# V32F20x_CM33 register map
File version: 1.0.3
CPU: CM33 r0p4, little endian, MPU, FPU, DSP, 3 interrupt priority bits, 8 SAU regions
Registers are 32-bit, read-write, reset 0x0 unless marked. A register's access mark holds for its fields unless they carry their own. Offsets are from the block's base; [hi:lo] are bit positions.

## FLASHA — FLASHA Peripheral Interface
Base 0x40208000
Same registers: FLASHB 0x4020C000, FLASH0 0x41208000, SEC_FLASHA 0x50208000, SEC_FLASHB 0x5020C000
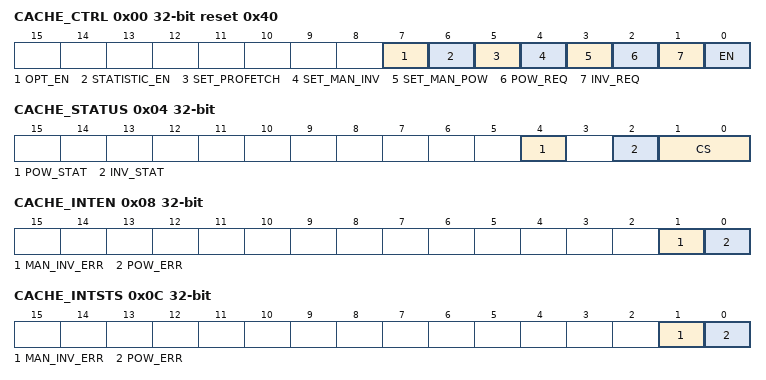
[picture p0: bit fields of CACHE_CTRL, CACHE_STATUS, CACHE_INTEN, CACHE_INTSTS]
0x00 CACHE_CTRL reset 0x40 — Flash cache Control register.
  [7] OPT_EN — Cache Performance Optimization enable control
  [6] STATISTIC_EN — Statistics logic enable control
  [5] SET_PROFETCH — Cache Pre-fetch enable control
  [4] SET_MAN_INV — Cache Invalidate control
  [3] SET_MAN_POW — Power control
  [2] POW_REQ — Manual SRAM power request.
  [1] INV_REQ — Manual invalidate request
  [0] EN — Cache enable control
0x04 CACHE_STATUS ro — Flash cache status Register.
  [4] POW_STAT — SRAM power acknowledges
  [2] INV_STAT — Invalidate Status
  [1:0] CS — Cache Status
0x08 CACHE_INTEN — Flash cache interrupt enable control register.
  [1] MAN_INV_ERR — Mask interrupt request on Manual Invalidation Error indication FLASH_CACHE_INTSTS
  [0] POW_ERR — Masking interrupt request on Power Error indication FLASH_CACHE_INTSTS
0x0C CACHE_INTSTS — Flash cache interrupt status control register.
  [1] MAN_INV_ERR — Manual invalidation error status
  [0] POW_ERR — SRAM power error
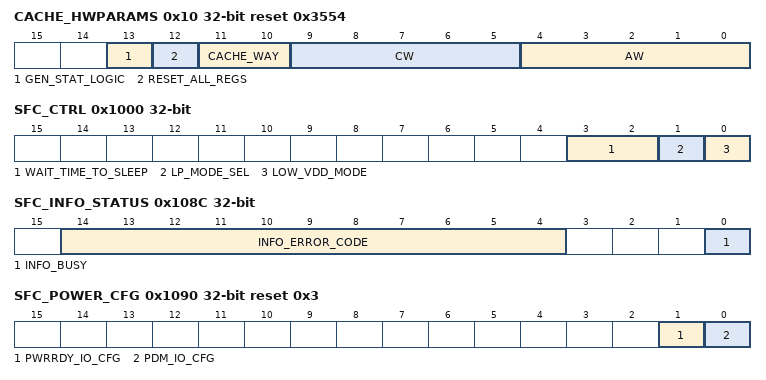
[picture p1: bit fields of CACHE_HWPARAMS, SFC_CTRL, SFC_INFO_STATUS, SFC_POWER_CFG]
0x10 CACHE_HWPARAMS ro reset 0x3554 — Flash cache hardware parameters register.
  [13] GEN_STAT_LOGIC — Indicates GEN_STAT_LOGIC hardware parameter value.
  [12] RESET_ALL_REGS — Indicates RESET_ALL_REGS hardware parameter value.
  [11:10] CACHE_WAY — Implementation defined value for number of cache ways
  [9:5] CW — Implementation-defined value for cache way width
  [4:0] AW — Implementation defined value for AHB Lite bus width for the flash address space
0x14 CACHE_CSHR — Flash cache statistic Hit Register.
  [31:0] CSHR — Counts the number of cache hits during cache look up
0x18 CACHE_CSMR — Flash cache statistic Miss Register.
  [31:0] CSMR — Counts the number of cache misses during cache look up
0x1000 SFC_CTRL — Control Registers
  [3:2] WAIT_TIME_TO_SLEEP — The time waiting to enter sleep mode when flash is idle
  [1] LP_MODE_SEL — Flash low power mode select
  [0] LOW_VDD_MODE
0x100C SFC_STATE — Status Register mainly for debugging
  [4:0] FLASH_STS — Flash working state for debug
0x1010 SFC_TAS reset 0x1 — Tas time configure.
  [1:0] R_TAS
0x1014 SFC_TPWS reset 0x1 — Tpws time configure.
  [2:0] R_TPWS
0x1018 SFC_TACC reset 0x1 — Tacc time configure.
  [2:0] R_TACC
0x101C SFC_TXYH reset 0x1 — Txyh time configure.
  [1:0] R_TXYH — Txyh time configure
0x1020 SFC_TWPR reset 0x1 — Twpr time configure.
  [1:0] W_TWPR — Twpr time configure
0x1024 SFC_TNVS reset 0x8 — Tnvs time configure.
  [3:0] W_TNVS — Tnvs time configure
0x1028 SFC_TPGS reset 0x2 — Tpgs time configure.
  [2:0] W_TPGS — Tpgs time configure
0x102C SFC_TPROG reset 0x9 — Tprog time configure.
  [3:0] W_TPROG — Tpgs time configure
0x1030 SFC_TPGH reset 0x2 — Tpgh time configure.
  [3:0] W_TPGH — Tpgh time configure
0x1034 SFC_TWHD reset 0x1 — Twhd time configure.
  [2:0] W_TWHD — Twhd time configure
0x1038 SFC_TADS reset 0x2 — Tadc time configure.
  [3:0] W_TADS — Tadc time configure
0x103C SFC_TADH reset 0x2 — Tadh time configure.
  [3:0] W_TADH — Tadh time configure
0x1040 SFC_TRCV reset 0xB — Trcv time configure.
  [4:0] W_TRCV — Trcv time configure
0x1044 SFC_TERASE reset 0x2AF8 — Terase time configure.
  [14:0] E_TERASE — Terase time configure
0x1048 SFC_TME reset 0x2AF8 — Tme time configure.
  [14:0] E_TME — Mass erase time configure
0x104C SFC_TNVH reset 0x6 — Tnvh time configure.
  [3:0] W_TNVH — Tnvh time configure
0x1050 SFC_TNVH1 reset 0x65 — Tnvh1 time configure.
  [7:0] W_TNVH1 — Tnvh1 time configure. Take 1us as unit.
0x1054 SFC_TWK reset 0x6 — Twk time configure.
  [3:0] S_TWK — Twk time configure
0x108C SFC_INFO_STATUS — INFO0 and INFO1 status.
  [14:4] INFO_ERROR_CODE — INFO0 and INFO1 access error type
  [0] INFO_BUSY — INFO0 or INFO1 is busy due to reading or writing or erasing operation
0x1090 SFC_POWER_CFG reset 0x3 — Flash pdm_io and pwrrdy_io configuration controls power supply
  [1] PWRRDY_IO_CFG — Flash power ready configuration.
  [0] PDM_IO_CFG — Flash configuration controls power down mode.
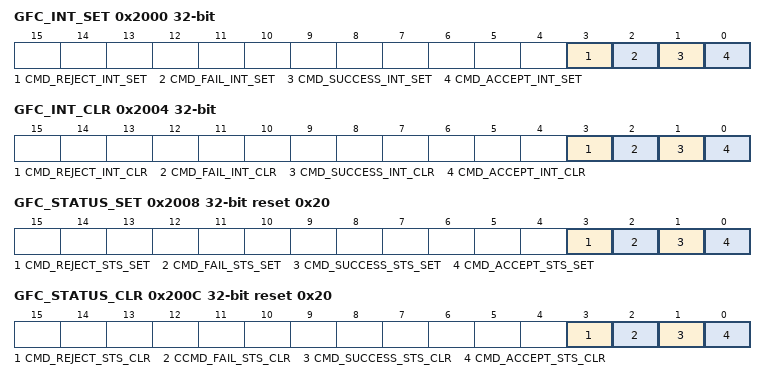
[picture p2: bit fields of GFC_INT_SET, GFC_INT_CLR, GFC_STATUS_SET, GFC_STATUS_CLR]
0x2000 GFC_INT_SET — GFC interrupt enable set register for enabling generation of interrupts
  [3] CMD_REJECT_INT_SET — Enables CMD_REJECT_IRQ bit to generate interrupts.
  [2] CMD_FAIL_INT_SET — Enables CMD_FAIL_IRQ bit to generate interrupts.
  [1] CMD_SUCCESS_INT_SET — Enables CMD_SUCCESS_IRQ bit to generate interrupts
  [0] CMD_ACCEPT_INT_SET — Enables CMD_ACCEPT_IRQ bit to generate interrupts.
0x2004 GFC_INT_CLR — GFC interrupt enable clear register for disabling generation of interrupt
  [3] CMD_REJECT_INT_CLR — Disables CMD_REJECT_IRQ bit
  [2] CMD_FAIL_INT_CLR — Disables CMD_FAIL_IRQ bit
  [1] CMD_SUCCESS_INT_CLR — Disables CMD_SUCCESS_IRQ bit
  [0] CMD_ACCEPT_INT_CLR — Disables CMD_ACCEPT_IRQ bit
0x2008 GFC_STATUS_SET reset 0x20 — GFC interrupt status set register for activating different interrupt sources
  [3] CMD_REJECT_STS_SET — Sets the status of the CMD_REJECT_IRQ bit.
  [2] CMD_FAIL_STS_SET — Sets the status of the CMD_FAIL_IRQ bit.
  [1] CMD_SUCCESS_STS_SET — Sets the status of the CMD_SUCCESS_IRQ bit.
  [0] CMD_ACCEPT_STS_SET — Sets the status of the CMD_ACCEPT_IRQ bit.
0x200C GFC_STATUS_CLR reset 0x20 — GFC interrupt status clear register for acknowledging different interrupt sources
  [3] CMD_REJECT_STS_CLR — Clears the status of the CMD_REJECT_IRQ bit.
  [2] CCMD_FAIL_STS_CLR — Clears the status of the CMD_FAIL_IRQ bit.
  [1] CMD_SUCCESS_STS_CLR — Clears the status of the CMD_SUCCESS_IRQ bit.
  [0] CMD_ACCEPT_STS_CLR — Clears the status of the CMD_ACCEPT_IRQ bit.
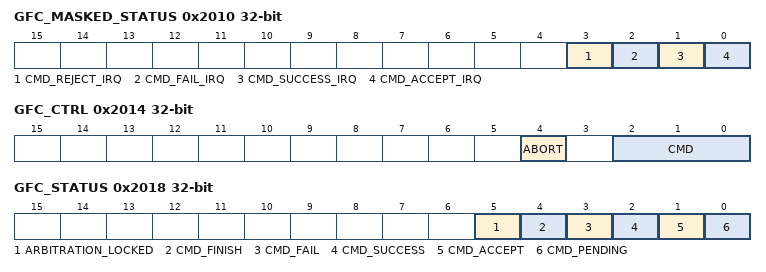
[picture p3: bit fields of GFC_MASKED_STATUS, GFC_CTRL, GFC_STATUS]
0x2010 GFC_MASKED_STATUS — GFC interrupt status register that shows if each interrupt is pending and is the cause of the interrupt line being asserted
  [3] CMD_REJECT_IRQ — When this bit reads 1 it means that CMD_REJECT_IRQ is the cause of the interrupt line being asserted
  [2] CMD_FAIL_IRQ — When this bit reads 1 it means that CMD_FAIL_IRQ is the cause of the interrupt line being asserted
  [1] CMD_SUCCESS_IRQ — When this bit reads 1 it means that CMD_SUCCESS_IRQ is the cause of the interrupt line being asserted
  [0] CMD_ACCEPT_IRQ — When this bit reads 1 it means that CMD_ACCEPT_IRQ is the cause of the interrupt line being asserted
0x2014 GFC_CTRL — GFC control register for initiating Flash accesses
  [4] ABORT — Abort currently ongoing command that is initiated towards the Flash from the APB interface
  [2:0] CMD — Initiate a command to the Flash for the address that is stored in the ADDR register and with the data that are stored in DATA0 register
0x2018 GFC_STATUS ro — GFC status register for showing the state of the Flash accesses
  [5] ARBITRATION_LOCKED
  [4] CMD_FINISH — Command finish
  [3] CMD_FAIL — Command fail
  [2] CMD_SUCCESS — Command success
  [1] CMD_ACCEPT — Command accept
  [0] CMD_PENDING — Command pening
0x201C GFC_ADDR — GFC address register for the Flash access.
  [21:0] ADDR — The 22 bit wide byte address for the current Flash access
0x2020 GFC_DATA0 — GFC data register for the Flash access containing read and write data bits[31:0]
  [31:0] DATA0 — Data register for the Flash access has read and write data bits 31 0
0x2024 GFC_DATA1 — GFC data register for the Flash access containing read data bits[63:32]
  [31:0] DATA1 — Data register for the Flash access has read data bits 63 32
0x2028 GFC_DATA2 — GFC data register for the flash access containing read data bits[95:64]
  [31:0] DATA2 — Data register for the Flash access has read data bits 95 64
0x202C GFC_DATA3 — GFC data register for the Flash access has read data bits[127:96]
  [31:0] DATA3 — Data register for the Flash access has read data bits 127 96
